# SERCOSIII register map
Registers are 32-bit, access not given, no defined reset value unless marked. A register's access mark holds for its fields unless they carry their own. Addresses are absolute; registers are grouped by the start of their names; [hi:lo] are bit positions; {n}, {i} and the like mark numbered series; 'fields as' and 'values as' point back to an identical list.

## SFR
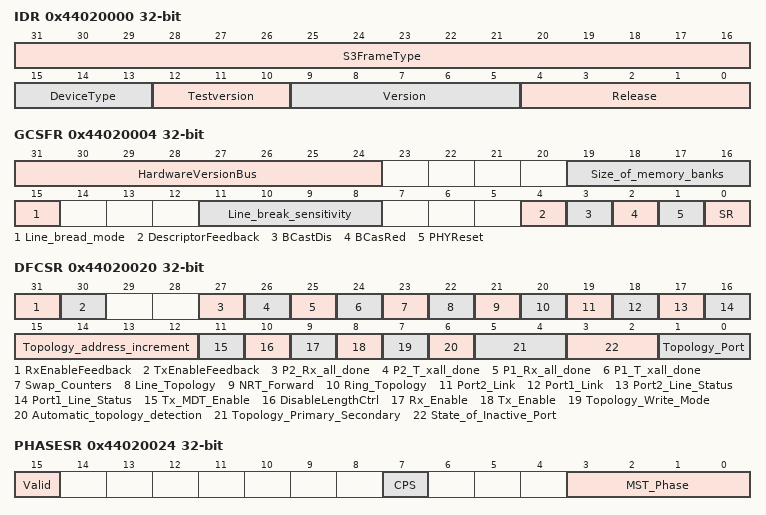
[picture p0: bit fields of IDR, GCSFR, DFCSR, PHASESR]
0x44020000 IDR ro
  [31:16] S3FrameType, [15:13] DeviceType, [12:10] Testversion, [9:5] Version, [4:0] Release
0x44020004 GCSFR
  [31:24] HardwareVersionBus, [19:16] Size_of_memory_banks, [15] Line_bread_mode, [11:8] Line_break_sensitivity, [4] DescriptorFeedback, [3] BCastDis, [2] BCasRed, [1] PHYReset, [0] SR
0x44020008 IER0
  [31:0] IE
0x44020010 IMR0
  [31:0] IM
0x44020018 IRR0
  [31:0] IR
0x44020020 DFCSR
  [31] RxEnableFeedback, [30] TxEnableFeedback, [27] P2_Rx_all_done, [26] P2_T_xall_done, [25] P1_Rx_all_done, [24] P1_T_xall_done, [23] Swap_Counters, [22] Line_Topology, [21] NRT_Forward, [20] Ring_Topology, [19] Port2_Link, [18] Port1_Link, [17] Port2_Line_Status, [16] Port1_Line_Status, [15:12] Topology_address_increment, [11] Tx_MDT_Enable, [10] DisableLengthCtrl, [9] Rx_Enable, [8] Tx_Enable, [7] Topology_Write_Mode, [6] Automatic_topology_detection, [5:4] Topology_Primary_Secondary, [3:2] State_of_Inactive_Port, [1:0] Topology_Port
0x44020024 PHASESR ro
  [15] Valid, [7] CPS, [3:0] MST_Phase
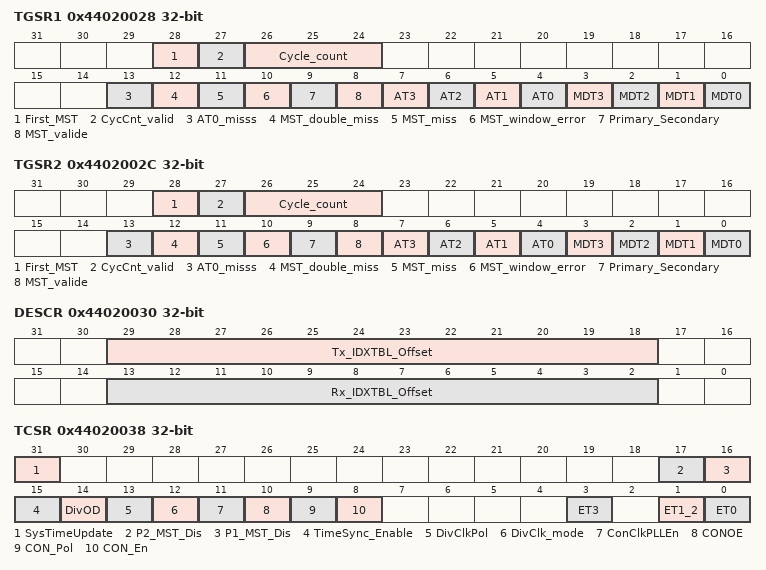
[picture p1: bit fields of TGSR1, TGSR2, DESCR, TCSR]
0x44020028 TGSR1
  [28] First_MST, [27] CycCnt_valid, [26:24] Cycle_count, [13] AT0_misss, [12] MST_double_miss, [11] MST_miss, [10] MST_window_error, [9] Primary_Secondary, [8] MST_valide, [n+4] AT{n} (n=0..3), [n] MDT{n} (n=0..3)
0x4402002C TGSR2
  fields as TGSR1
0x44020030 DESCR
  [29:18] Tx_IDXTBL_Offset, [13:2] Rx_IDXTBL_Offset
0x44020034 STRBR ro
  [25:0] TCNT
0x44020038 TCSR
  [31] SysTimeUpdate, [17] P2_MST_Dis, [16] P1_MST_Dis, [15] TimeSync_Enable, [14] DivOD, [13] DivClkPol, [12] DivClk_mode, [11] ConClkPLLEn, [10] CONOE, [9] CON_Pol, [8] CON_En, [3] ET3, [1] ET1_2, [0] ET0
0x4402003C TRDLY
  [19:0] Ringdelay
0x44020040 TDMST1
  [19:0] Time_Delay_MST
0x44020044 TDMST2
  [19:0] Time_Delay_MST
0x44020048 SCR1 ro
  [19:0] Sync_Count
0x4402004C SCR2 ro
  [19:0] Sync_Count
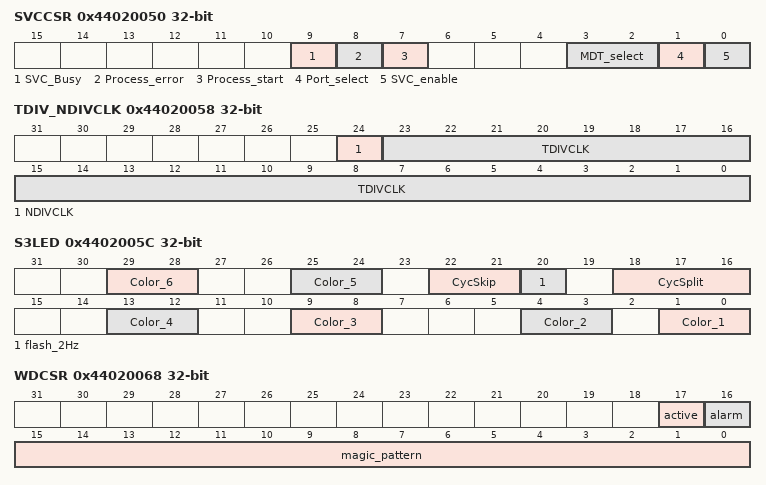
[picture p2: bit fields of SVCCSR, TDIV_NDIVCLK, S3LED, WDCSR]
0x44020050 SVCCSR
  [9] SVC_Busy, [8] Process_error, [7] Process_start, [3:2] MDT_select, [1] Port_select, [0] SVC_enable
0x44020054 DTDIVCLK
  [25:0] DTDIVCLK
0x44020058 TDIV_NDIVCLK
  [24] NDIVCLK, [23:0] TDIVCLK
0x4402005C S3LED
  [29:28] Color_6, [25:24] Color_5, [22:21] CycSkip, [20] flash_2Hz, [18:16] CycSplit, [13:12] Color_4, [9:8] Color_3, [4:3] Color_2, [1:0] Color_1
0x44020068 WDCSR
  [17] active, [16] alarm, [15:0] magic_pattern
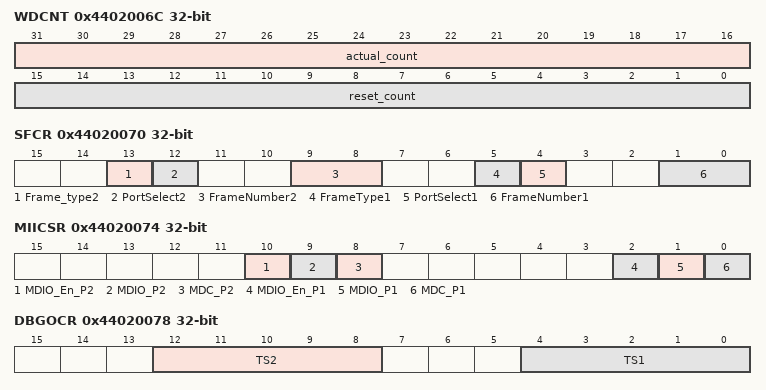
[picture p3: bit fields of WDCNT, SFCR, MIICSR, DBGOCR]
0x4402006C WDCNT
  [31:16] actual_count, [15:0] reset_count
0x44020070 SFCR
  [13] Frame_type2, [12] PortSelect2, [9:8] FrameNumber2, [5] FrameType1, [4] PortSelect1, [1:0] FrameNumber1
0x44020074 MIICSR
  [10] MDIO_En_P2, [9] MDIO_P2, [8] MDC_P2, [2] MDIO_En_P1, [1] MDIO_P1, [0] MDC_P1
0x44020078 DBGOCR
  [12:8] TS2, [4:0] TS1
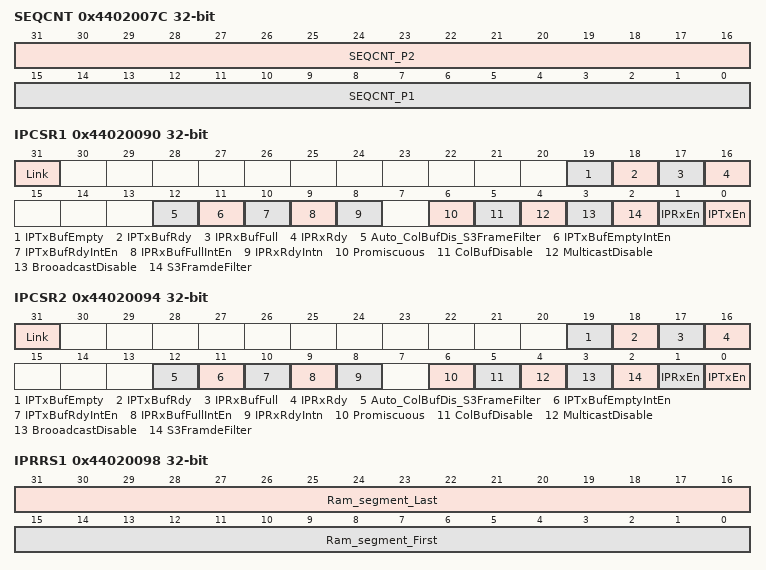
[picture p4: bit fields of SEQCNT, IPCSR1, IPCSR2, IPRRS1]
0x4402007C SEQCNT
  [31:16] SEQCNT_P2, [15:0] SEQCNT_P1
0x44020090 IPCSR1
  [31] Link, [19] IPTxBufEmpty, [18] IPTxBufRdy, [17] IPRxBufFull, [16] IPRxRdy, [12] Auto_ColBufDis_S3FrameFilter, [11] IPTxBufEmptyIntEn, [10] IPTxBufRdyIntEn, [9] IPRxBufFullIntEn, [8] IPRxRdyIntn, [6] Promiscuous, [5] ColBufDisable, [4] MulticastDisable, [3] BrooadcastDisable, [2] S3FramdeFilter, [1] IPRxEn, [0] IPTxEn
0x44020094 IPCSR2
  fields as IPCSR1
0x44020098 IPRRS1
  [31:16] Ram_segment_Last, [15:0] Ram_segment_First
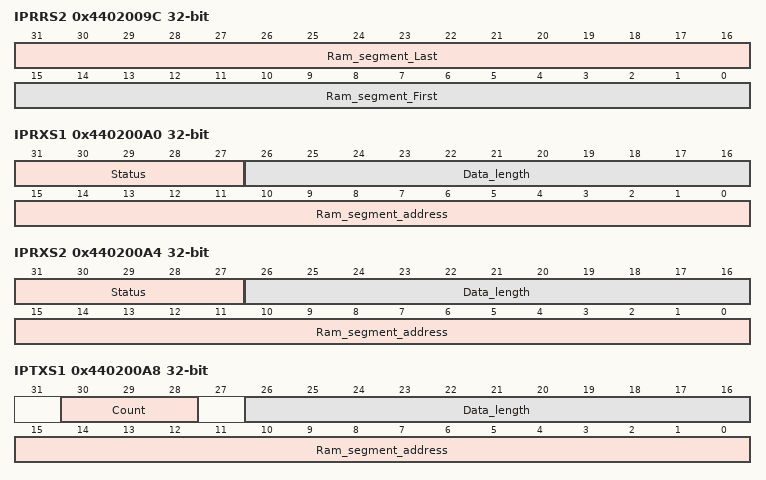
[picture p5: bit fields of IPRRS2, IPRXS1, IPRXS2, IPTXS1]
0x4402009C IPRRS2
  [31:16] Ram_segment_Last, [15:0] Ram_segment_First
0x440200A0 IPRXS1
  [31:27] Status, [26:16] Data_length, [15:0] Ram_segment_address
0x440200A4 IPRXS2
  [31:27] Status, [26:16] Data_length, [15:0] Ram_segment_address
0x440200A8 IPTXS1
  [30:28] Count, [26:16] Data_length, [15:0] Ram_segment_address
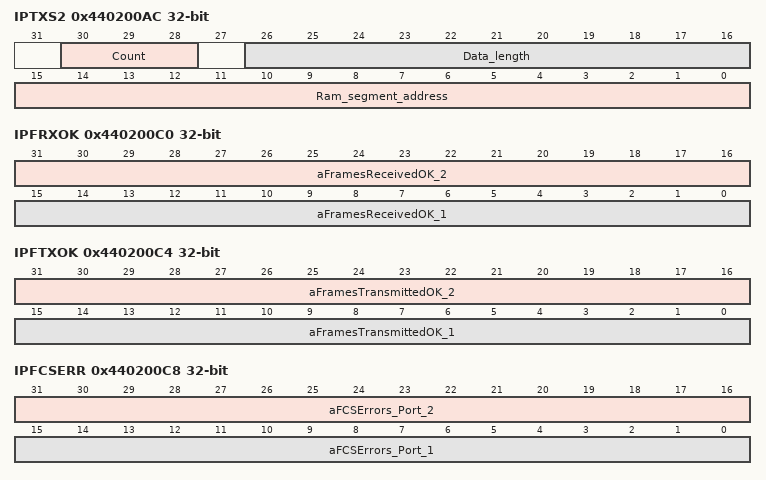
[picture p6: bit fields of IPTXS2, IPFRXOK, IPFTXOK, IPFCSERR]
0x440200AC IPTXS2
  [30:28] Count, [26:16] Data_length, [15:0] Ram_segment_address
0x440200B0 IPLASTFL
  [10:0] length
0x440200C0 IPFRXOK ro
  [31:16] aFramesReceivedOK_2, [15:0] aFramesReceivedOK_1
0x440200C4 IPFTXOK ro
  [31:16] aFramesTransmittedOK_2, [15:0] aFramesTransmittedOK_1
0x440200C8 IPFCSERR ro
  [31:16] aFCSErrors_Port_2, [15:0] aFCSErrors_Port_1
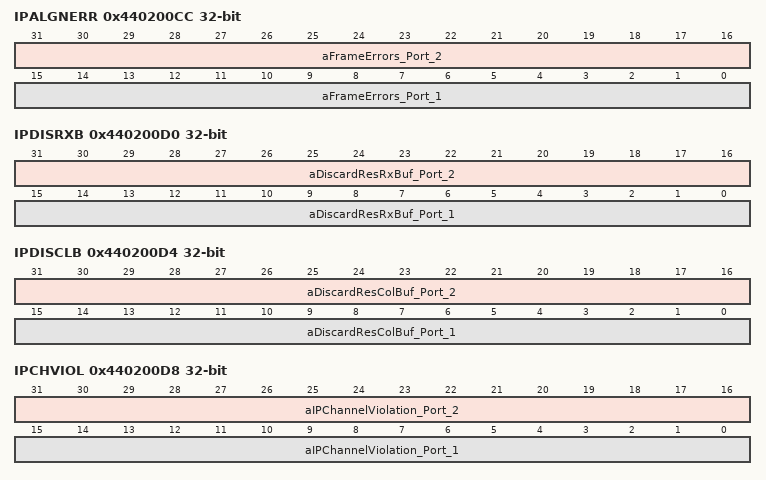
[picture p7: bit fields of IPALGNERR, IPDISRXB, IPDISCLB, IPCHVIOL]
0x440200CC IPALGNERR ro
  [31:16] aFrameErrors_Port_2, [15:0] aFrameErrors_Port_1
0x440200D0 IPDISRXB ro
  [31:16] aDiscardResRxBuf_Port_2, [15:0] aDiscardResRxBuf_Port_1
0x440200D4 IPDISCLB ro
  [31:16] aDiscardResColBuf_Port_2, [15:0] aDiscardResColBuf_Port_1
0x440200D8 IPCHVIOL ro
  [31:16] aIPChannelViolation_Port_2, [15:0] aIPChannelViolation_Port_1
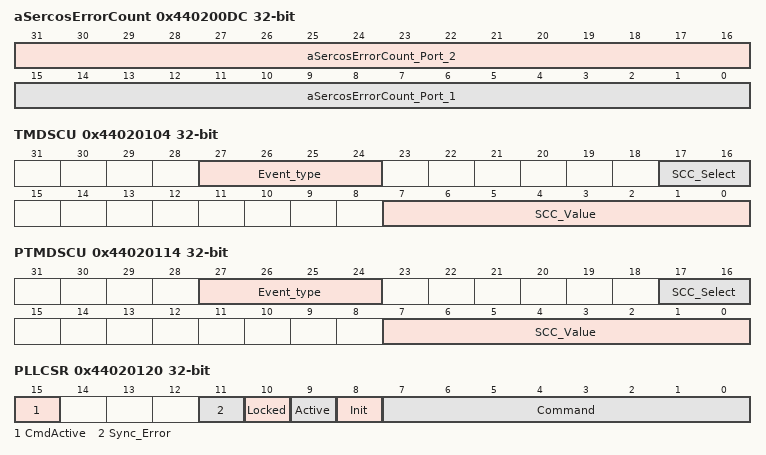
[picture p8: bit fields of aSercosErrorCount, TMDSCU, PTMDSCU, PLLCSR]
0x440200DC aSercosErrorCount
  [31:16] aSercosErrorCount_Port_2, [15:0] aSercosErrorCount_Port_1
0x440200E0 MSTLMAX
  [15:0] value
0x440200E4 MSTLSUM
  [15:0] value
0x440200E8 MSTACT
  [15:0] value
0x44020100 TMDSCL
  [26:0] Event_TCNT_Value
0x44020104 TMDSCU
  [27:24] Event_type, [17:16] SCC_Select, [7:0] SCC_Value
0x44020108 TMDSCSEL
0x44020110 PTMDSCL
  [26:0] Event_TCNT_Value
0x44020114 PTMDSCU
  [27:24] Event_type, [17:16] SCC_Select, [7:0] SCC_Value
0x44020118 PTMDSCSEL
0x44020120 PLLCSR
  [15] CmdActive, [11] Sync_Error, [10] Locked, [9] Active, [8] Init, [7:0] Command
0x44020124 TCNTCYCR
  [25:0] TCNT_Cycletime
0x44020130 STNS ro
  [29:0] Nanoseconds
0x44020134 STSEC ro
  [31:0] Seconds
0x44020138 STNSTSR ro
  [29:0] Nanoseconds
0x4402013C STSECTSR ro
  [31:0] Seconds
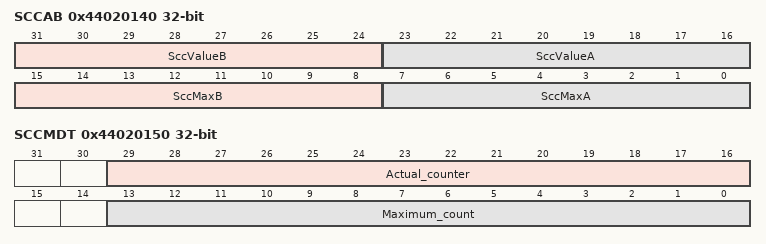
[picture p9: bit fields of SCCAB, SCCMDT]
0x44020140 SCCAB
  [31:24] SccValueB, [23:16] SccValueA, [15:8] SccMaxB, [7:0] SccMaxA
0x44020150 SCCMDT ro
  [29:16] Actual_counter, [13:0] Maximum_count
